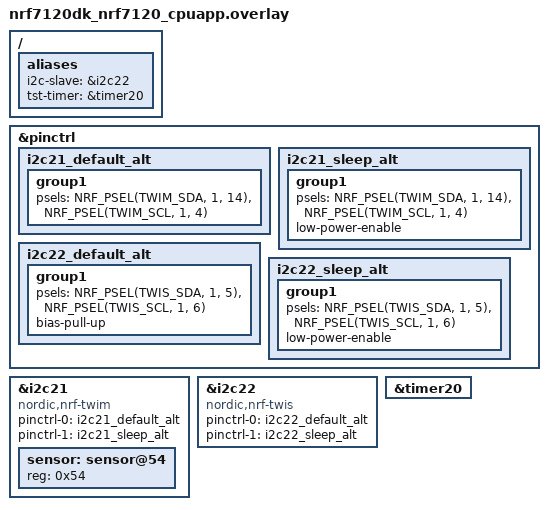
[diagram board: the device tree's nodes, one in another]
/*
 * SDA = P1.05 and P1.14
 * SCL = P1.06 and P1.04
 */

/ {
	aliases {
		i2c-slave = &i2c22;
		tst-timer = &timer20;
	};
};

&pinctrl {
	i2c21_default_alt: i2c21_default_alt {
		group1 {
			psels = <NRF_PSEL(TWIM_SDA, 1, 14)>,
				<NRF_PSEL(TWIM_SCL, 1, 4)>;
		};
	};

	i2c21_sleep_alt: i2c21_sleep_alt {
		group1 {
			psels = <NRF_PSEL(TWIM_SDA, 1, 14)>,
				<NRF_PSEL(TWIM_SCL, 1, 4)>;
			low-power-enable;
		};
	};

	i2c22_default_alt: i2c22_default_alt {
		group1 {
			psels = <NRF_PSEL(TWIS_SDA, 1, 5)>,
				<NRF_PSEL(TWIS_SCL, 1, 6)>;
			bias-pull-up;
		};
	};

	i2c22_sleep_alt: i2c22_sleep_alt {
		group1 {
			psels = <NRF_PSEL(TWIS_SDA, 1, 5)>,
				<NRF_PSEL(TWIS_SCL, 1, 6)>;
			low-power-enable;
		};
	};
};

dut_twim: &i2c21 {
	compatible = "nordic,nrf-twim";
	status = "okay";
	pinctrl-0 = <&i2c21_default_alt>;
	pinctrl-1 = <&i2c21_sleep_alt>;
	pinctrl-names = "default", "sleep";

	sensor: sensor@54 {
		reg = <0x54>;
	};
};

dut_twis: &i2c22 {
	compatible = "nordic,nrf-twis";
	status = "okay";
	pinctrl-0 = <&i2c22_default_alt>;
	pinctrl-1 = <&i2c22_sleep_alt>;
	pinctrl-names = "default", "sleep";
};

&timer20 {
	status = "okay";
};
